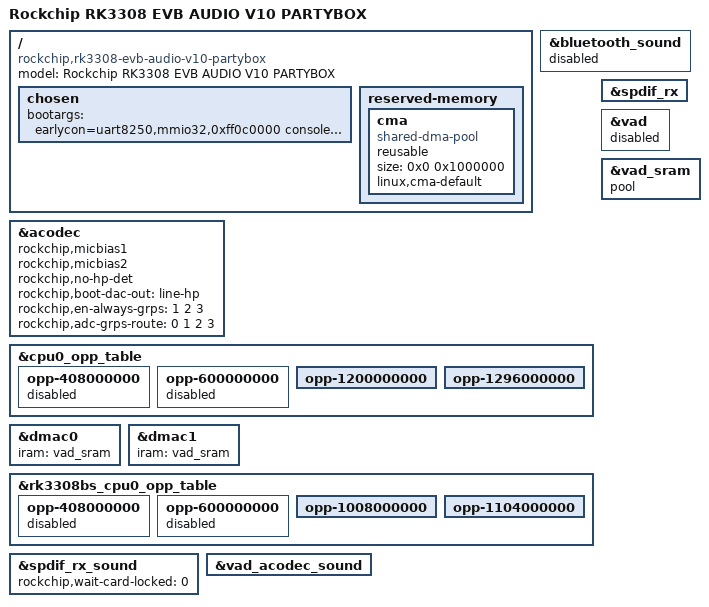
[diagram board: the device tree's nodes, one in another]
// SPDX-License-Identifier: (GPL-2.0+ OR MIT)
/*
 * Copyright (c) 2022 Rockchip Electronics Co., Ltd.
 */

/dts-v1/;

#include "rk3308-evb-audio-v10-display-rgb.dts"

/ {
	model = "Rockchip RK3308 EVB AUDIO V10 PARTYBOX";
	compatible = "rockchip,rk3308-evb-audio-v10-partybox", "rockchip,rk3308";

	chosen {
		bootargs = "earlycon=uart8250,mmio32,0xff0c0000 console=ttyFIQ0 root=PARTUUID=614e0000-0000 rootfstype=squashfs rootwait snd_aloop.index=7 snd_aloop.use_raw_jiffies=1 isolcpus=2,3 nohz_full=2,3 snd_soc_core.prealloc_buffer_size_kbytes=16";
	};

	reserved-memory {
		#address-cells = <2>;
		#size-cells = <2>;
		ranges;

		cma {
			compatible = "shared-dma-pool";
			reusable;
			size = <0x0 0x1000000>;
			linux,cma-default;
		};
	};
};

&acodec {
	rockchip,micbias1;
	rockchip,micbias2;
	rockchip,no-hp-det;
	rockchip,boot-dac-out = "line-hp";
	rockchip,en-always-grps = <1 2 3>;
	rockchip,adc-grps-route = <0 1 2 3>;
};

&bluetooth_sound {
	status = "disabled";
};

&cpu0_opp_table {
	opp-408000000 {
		status = "disabled";
	};
	opp-600000000 {
		status = "disabled";
	};
	opp-1200000000 {
		status = "okay";
	};
	opp-1296000000 {
		status = "okay";
	};
};

&dmac0 {
	iram = <&vad_sram>;
};

&dmac1 {
	iram = <&vad_sram>;
};

&rk3308bs_cpu0_opp_table {
	opp-408000000 {
		status = "disabled";
	};
	opp-600000000 {
		status = "disabled";
	};
	opp-1008000000 {
		status = "okay";
	};
	opp-1104000000 {
		status = "okay";
	};
};

&spdif_rx {
	status = "okay";
};

&spdif_rx_sound {
	status = "okay";
	rockchip,wait-card-locked = <0>;
};

&vad {
	status = "disabled";
};

&vad_acodec_sound {
	status = "okay";
};

&vad_sram {
	pool;
};
